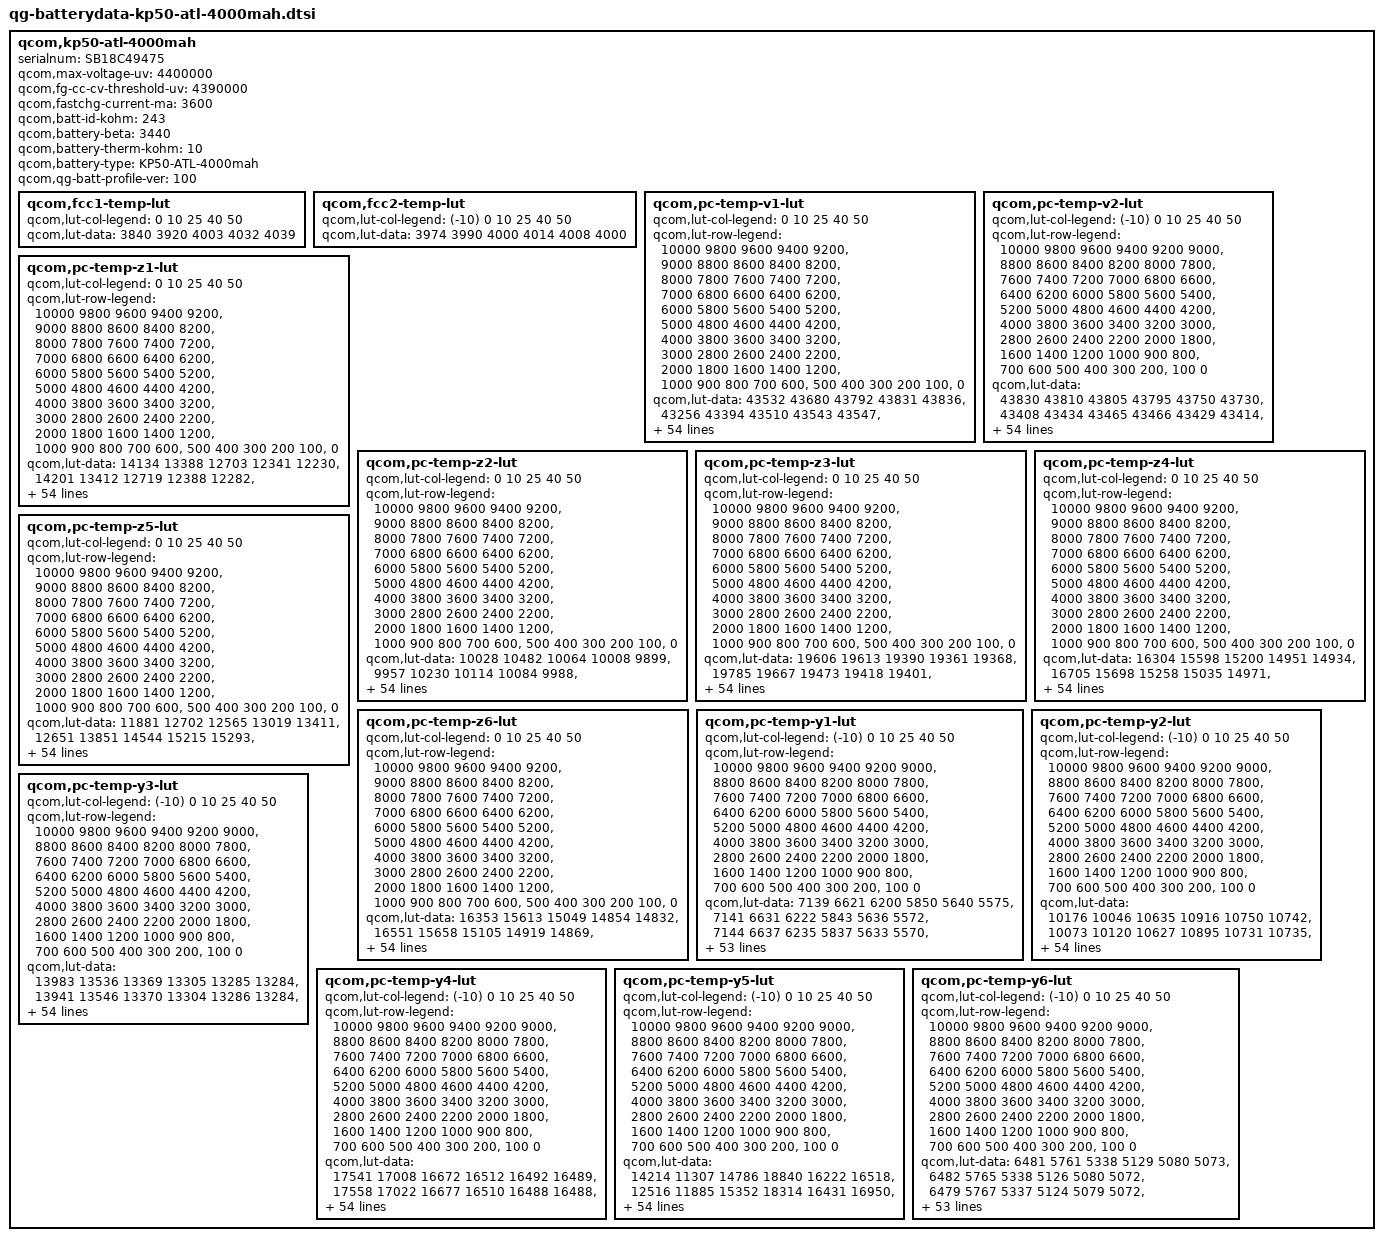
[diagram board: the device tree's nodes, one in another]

qcom,kp50-atl-4000mah {
    /* 3939372_Lenovo_KP50_ATL_4000mAh_PM6150_FG_averaged_MasterSlave_Mar25th2019 */
    serialnum = "SB18C49475";
    qcom,max-voltage-uv = <4400000>;
    qcom,fg-cc-cv-threshold-uv = <4390000>;
    qcom,fastchg-current-ma = <3600>;
    qcom,batt-id-kohm = <243>;
    qcom,battery-beta = <3440>;
    qcom,battery-therm-kohm = <10>;
    qcom,battery-type = "KP50-ATL-4000mah";
    qcom,qg-batt-profile-ver = <100>;

	qcom,fcc1-temp-lut {
		qcom,lut-col-legend = <0 10 25 40 50>;
		qcom,lut-data = <3840 3920 4003 4032 4039>;
	};

	qcom,fcc2-temp-lut {
		qcom,lut-col-legend = <(-10) 0 10 25 40 50>;
		qcom,lut-data = <3974 3990 4000 4014 4008 4000>;
	};

	qcom,pc-temp-v1-lut {
		qcom,lut-col-legend = <0 10 25 40 50>;
		qcom,lut-row-legend = <10000 9800 9600 9400 9200>,
			<9000 8800 8600 8400 8200>,
			<8000 7800 7600 7400 7200>,
			<7000 6800 6600 6400 6200>,
			<6000 5800 5600 5400 5200>,
			<5000 4800 4600 4400 4200>,
			<4000 3800 3600 3400 3200>,
			<3000 2800 2600 2400 2200>,
			<2000 1800 1600 1400 1200>,
			<1000 900 800 700 600>,
			<500 400 300 200 100>,
			<0>;
		qcom,lut-data = <43532 43680 43792 43831 43836>,
			<43256 43394 43510 43543 43547>,
			<43004 43131 43248 43283 43290>,
			<42765 42888 42996 43036 43046>,
			<42530 42654 42754 42796 42807>,
			<42302 42420 42519 42563 42575>,
			<42079 42190 42287 42331 42344>,
			<41863 41967 42060 42101 42114>,
			<41653 41747 41835 41874 41886>,
			<41452 41533 41611 41650 41662>,
			<41262 41330 41393 41429 41440>,
			<41068 41136 41188 41216 41224>,
			<40859 40937 40990 41009 41012>,
			<40641 40725 40786 40807 40807>,
			<40421 40511 40570 40600 40604>,
			<40193 40308 40364 40399 40409>,
			<39992 40113 40176 40214 40228>,
			<39840 39945 40003 40041 40058>,
			<39712 39807 39848 39877 39894>,
			<39588 39679 39717 39732 39743>,
			<39465 39541 39572 39581 39586>,
			<39345 39399 39379 39385 39389>,
			<39225 39238 39162 39154 39157>,
			<39106 39011 38967 38961 38964>,
			<38980 38775 38774 38803 38813>,
			<38831 38634 38627 38672 38687>,
			<38680 38542 38543 38574 38587>,
			<38564 38473 38480 38496 38505>,
			<38470 38420 38417 38420 38421>,
			<38396 38378 38353 38345 38329>,
			<38345 38337 38295 38275 38244>,
			<38307 38297 38241 38206 38177>,
			<38273 38259 38191 38141 38120>,
			<38243 38223 38142 38083 38062>,
			<38216 38189 38096 38035 38005>,
			<38187 38154 38051 37988 37949>,
			<38157 38121 38011 37941 37893>,
			<38121 38081 37972 37891 37836>,
			<38070 38021 37914 37825 37763>,
			<38002 37935 37828 37730 37663>,
			<37915 37836 37728 37624 37551>,
			<37790 37718 37620 37517 37442>,
			<37651 37583 37495 37397 37321>,
			<37496 37425 37336 37242 37159>,
			<37350 37277 37192 37105 37030>,
			<37248 37177 37092 37015 36954>,
			<37219 37150 37065 36983 36921>,
			<37191 37126 37044 36963 36900>,
			<37168 37103 37025 36941 36876>,
			<37130 37064 36978 36878 36802>,
			<36915 36840 36743 36610 36512>,
			<36475 36400 36312 36170 36068>,
			<35905 35827 35741 35595 35492>,
			<35126 35050 34963 34812 34707>,
			<33885 33812 33759 33588 33477>,
			<30000 30000 30000 30000 30000>;
	};

	qcom,pc-temp-v2-lut {
		qcom,lut-col-legend = <(-10) 0 10 25 40 50>;
		qcom,lut-row-legend = <10000 9800 9600 9400 9200 9000>,
			<8800 8600 8400 8200 8000 7800>,
			<7600 7400 7200 7000 6800 6600>,
			<6400 6200 6000 5800 5600 5400>,
			<5200 5000 4800 4600 4400 4200>,
			<4000 3800 3600 3400 3200 3000>,
			<2800 2600 2400 2200 2000 1800>,
			<1600 1400 1200 1000 900 800>,
			<700 600 500 400 300 200>,
			<100 0>;
		qcom,lut-data = <43830 43810 43805 43795 43750 43730>,
			<43408 43434 43465 43466 43429 43414>,
			<43034 43095 43154 43164 43133 43121>,
			<42720 42801 42877 42893 42865 42856>,
			<42454 42547 42630 42650 42623 42616>,
			<42211 42304 42393 42415 42389 42382>,
			<41984 42065 42153 42179 42155 42149>,
			<41770 41831 41919 41948 41923 41918>,
			<41551 41596 41692 41720 41696 41691>,
			<41320 41353 41471 41494 41472 41466>,
			<41118 41142 41259 41275 41252 41246>,
			<40983 40994 41062 41063 41037 41031>,
			<40863 40861 40870 40857 40827 40821>,
			<40632 40661 40660 40651 40624 40618>,
			<40134 40356 40428 40445 40425 40420>,
			<39693 40055 40205 40245 40234 40230>,
			<39496 39814 40009 40049 40051 40051>,
			<39356 39596 39823 39864 39876 39878>,
			<39210 39400 39629 39700 39712 39714>,
			<39064 39223 39429 39559 39563 39563>,
			<38910 39056 39233 39399 39398 39399>,
			<38717 38894 39039 39176 39185 39190>,
			<38512 38740 38855 38941 38960 38967>,
			<38376 38581 38699 38762 38779 38786>,
			<38290 38409 38562 38613 38625 38630>,
			<38219 38266 38440 38487 38494 38497>,
			<38153 38167 38334 38380 38385 38386>,
			<38094 38089 38237 38286 38289 38289>,
			<38038 38029 38145 38198 38202 38199>,
			<37987 37982 38053 38116 38124 38117>,
			<37938 37939 37977 38043 38054 38044>,
			<37890 37898 37917 37976 37990 37980>,
			<37841 37858 37867 37915 37931 37921>,
			<37791 37819 37825 37857 37868 37856>,
			<37740 37781 37792 37804 37803 37786>,
			<37687 37740 37758 37750 37730 37706>,
			<37631 37692 37720 37693 37640 37603>,
			<37573 37638 37679 37633 37545 37490>,
			<37507 37574 37624 37563 37463 37399>,
			<37428 37500 37553 37484 37390 37324>,
			<37343 37415 37469 37399 37311 37246>,
			<37258 37316 37363 37308 37220 37157>,
			<37172 37201 37240 37201 37115 37056>,
			<37095 37072 37102 37063 36983 36922>,
			<37019 36945 36969 36944 36877 36818>,
			<36936 36847 36876 36885 36828 36770>,
			<36884 36808 36846 36871 36816 36760>,
			<36826 36763 36804 36853 36802 36743>,
			<36754 36701 36758 36818 36766 36708>,
			<36623 36593 36664 36729 36658 36581>,
			<36359 36348 36397 36424 36321 36226>,
			<35915 35890 35905 35932 35815 35718>,
			<35270 35238 35255 35288 35156 35057>,
			<34349 34308 34341 34414 34261 34169>,
			<32925 32874 33061 33169 32975 32863>,
			<29479 28325 27871 28921 27928 27833>;
	};

	qcom,pc-temp-z1-lut {
		qcom,lut-col-legend = <0 10 25 40 50>;
		qcom,lut-row-legend = <10000 9800 9600 9400 9200>,
			<9000 8800 8600 8400 8200>,
			<8000 7800 7600 7400 7200>,
			<7000 6800 6600 6400 6200>,
			<6000 5800 5600 5400 5200>,
			<5000 4800 4600 4400 4200>,
			<4000 3800 3600 3400 3200>,
			<3000 2800 2600 2400 2200>,
			<2000 1800 1600 1400 1200>,
			<1000 900 800 700 600>,
			<500 400 300 200 100>,
			<0>;
		qcom,lut-data = <14134 13388 12703 12341 12230>,
			<14201 13412 12719 12388 12282>,
			<14175 13418 12725 12390 12288>,
			<14146 13411 12724 12390 12290>,
			<14120 13401 12712 12388 12289>,
			<14092 13388 12697 12383 12289>,
			<14082 13373 12686 12380 12289>,
			<14092 13362 12676 12377 12291>,
			<14102 13351 12668 12376 12293>,
			<14093 13340 12660 12378 12298>,
			<14052 13329 12655 12381 12303>,
			<14004 13315 12653 12382 12305>,
			<13956 13298 12653 12382 12306>,
			<13910 13265 12651 12382 12306>,
			<13884 13236 12647 12380 12305>,
			<13868 13230 12644 12378 12304>,
			<13858 13232 12643 12378 12305>,
			<13857 13238 12644 12380 12307>,
			<13859 13252 12646 12382 12309>,
			<13862 13266 12652 12385 12311>,
			<13868 13269 12657 12388 12313>,
			<13876 13271 12661 12389 12314>,
			<13889 13271 12665 12390 12315>,
			<13908 13275 12668 12391 12316>,
			<13921 13280 12673 12393 12318>,
			<13920 13284 12677 12396 12320>,
			<13915 13286 12680 12400 12323>,
			<13913 13286 12684 12403 12327>,
			<13901 13286 12689 12407 12331>,
			<13890 13287 12695 12413 12334>,
			<13891 13293 12702 12418 12338>,
			<13898 13304 12708 12423 12343>,
			<13905 13317 12714 12428 12348>,
			<13915 13335 12722 12434 12353>,
			<13929 13355 12730 12441 12359>,
			<13951 13360 12740 12448 12365>,
			<13989 13358 12749 12453 12370>,
			<14016 13355 12757 12459 12375>,
			<14028 13358 12766 12465 12379>,
			<14041 13370 12775 12471 12383>,
			<14056 13382 12784 12478 12387>,
			<14091 13396 12795 12485 12392>,
			<14121 13414 12805 12492 12398>,
			<14143 13447 12809 12497 12402>,
			<14158 13435 12826 12505 12407>,
			<14120 13475 12837 12508 12408>,
			<14130 13443 12827 12508 12408>,
			<14122 13440 12834 12509 12410>,
			<14089 13423 12833 12515 12415>,
			<14129 13444 12839 12520 12420>,
			<14177 13442 12853 12527 12427>,
			<14147 13459 12870 12538 12435>,
			<14269 13501 12882 12548 12447>,
			<14263 13534 12909 12567 12463>,
			<14263 13534 12909 12567 12463>,
			<14263 13534 12909 12567 12463>;
	};

	qcom,pc-temp-z2-lut {
		qcom,lut-col-legend = <0 10 25 40 50>;
		qcom,lut-row-legend = <10000 9800 9600 9400 9200>,
			<9000 8800 8600 8400 8200>,
			<8000 7800 7600 7400 7200>,
			<7000 6800 6600 6400 6200>,
			<6000 5800 5600 5400 5200>,
			<5000 4800 4600 4400 4200>,
			<4000 3800 3600 3400 3200>,
			<3000 2800 2600 2400 2200>,
			<2000 1800 1600 1400 1200>,
			<1000 900 800 700 600>,
			<500 400 300 200 100>,
			<0>;
		qcom,lut-data = <10028 10482 10064 10008 9899>,
			<9957 10230 10114 10084 9988>,
			<10007 10128 10203 10180 10110>,
			<10061 10116 10227 10219 10177>,
			<10084 10106 10210 10205 10176>,
			<10102 10089 10188 10178 10172>,
			<10110 10069 10164 10154 10164>,
			<10114 10053 10138 10125 10144>,
			<10117 10040 10117 10106 10134>,
			<10115 10032 10098 10094 10127>,
			<10101 10028 10089 10087 10114>,
			<10082 10025 10178 10089 10109>,
			<10052 10025 10392 10092 10102>,
			<10017 10033 10454 10093 10096>,
			<9996 10048 10301 10100 10100>,
			<9982 10091 10152 10110 10106>,
			<9974 10217 10133 10078 10079>,
			<9978 10297 10123 9982 9993>,
			<9990 10247 10123 9942 9952>,
			<10002 10164 10139 9955 9966>,
			<10013 10158 10166 9982 9996>,
			<10025 10184 10246 10093 10114>,
			<10036 10208 10350 10322 10388>,
			<10049 10225 10360 10395 10493>,
			<10064 10238 10293 10215 10289>,
			<10084 10248 10235 10037 10071>,
			<10104 10256 10212 10037 10060>,
			<10118 10259 10196 10061 10079>,
			<10130 10258 10201 10072 10122>,
			<10138 10256 10240 10074 10340>,
			<10139 10254 10272 10076 10538>,
			<10139 10251 10282 10137 10476>,
			<10140 10249 10289 10264 10277>,
			<10145 10251 10294 10293 10129>,
			<10152 10258 10299 10199 10016>,
			<10158 10264 10302 10112 9952>,
			<10166 10269 10302 10099 9968>,
			<10175 10275 10302 10101 10015>,
			<10185 10285 10311 10125 10056>,
			<10196 10299 10348 10225 10098>,
			<10208 10309 10373 10298 10122>,
			<10219 10316 10366 10283 10121>,
			<10235 10323 10358 10256 10118>,
			<10262 10329 10368 10248 10222>,
			<10497 10450 10399 10218 10216>,
			<10535 10508 10409 10183 10113>,
			<10546 10506 10386 10170 10086>,
			<10556 10505 10353 10181 10096>,
			<10542 10513 10360 10196 10125>,
			<10489 10603 10399 10276 10196>,
			<10630 10588 10408 10201 10093>,
			<10589 10533 10337 10041 9935>,
			<10332 10464 10261 9987 9880>,
			<10066 10330 10188 9964 9846>,
			<10066 10330 10188 9964 9846>,
			<10066 10330 10188 9964 9846>;
	};

	qcom,pc-temp-z3-lut {
		qcom,lut-col-legend = <0 10 25 40 50>;
		qcom,lut-row-legend = <10000 9800 9600 9400 9200>,
			<9000 8800 8600 8400 8200>,
			<8000 7800 7600 7400 7200>,
			<7000 6800 6600 6400 6200>,
			<6000 5800 5600 5400 5200>,
			<5000 4800 4600 4400 4200>,
			<4000 3800 3600 3400 3200>,
			<3000 2800 2600 2400 2200>,
			<2000 1800 1600 1400 1200>,
			<1000 900 800 700 600>,
			<500 400 300 200 100>,
			<0>;
		qcom,lut-data = <19606 19613 19390 19361 19368>,
			<19785 19667 19473 19418 19401>,
			<19851 19680 19509 19440 19419>,
			<19877 19692 19520 19451 19430>,
			<19874 19700 19525 19457 19438>,
			<19859 19698 19527 19460 19444>,
			<19841 19691 19523 19460 19446>,
			<19813 19683 19514 19460 19448>,
			<19786 19672 19508 19459 19449>,
			<19775 19660 19504 19457 19448>,
			<19771 19652 19501 19453 19444>,
			<19772 19644 19501 19448 19439>,
			<19782 19636 19506 19440 19433>,
			<19796 19624 19507 19434 19427>,
			<19801 19614 19497 19432 19423>,
			<19801 19611 19486 19430 19419>,
			<19798 19612 19477 19426 19412>,
			<19778 19610 19467 19418 19403>,
			<19739 19581 19457 19409 19395>,
			<19715 19544 19444 19398 19386>,
			<19702 19539 19437 19391 19380>,
			<19695 19549 19446 19395 19383>,
			<19695 19561 19463 19408 19393>,
			<19698 19574 19465 19412 19396>,
			<19704 19587 19458 19396 19378>,
			<19720 19589 19449 19378 19358>,
			<19740 19587 19441 19370 19353>,
			<19744 19583 19435 19365 19351>,
			<19741 19579 19434 19364 19354>,
			<19735 19574 19435 19371 19398>,
			<19728 19569 19438 19383 19442>,
			<19717 19565 19444 19401 19440>,
			<19707 19562 19451 19425 19427>,
			<19695 19560 19456 19431 19416>,
			<19684 19559 19461 19423 19405>,
			<19676 19557 19464 19413 19396>,
			<19669 19553 19457 19402 19386>,
			<19662 19549 19446 19393 19377>,
			<19655 19546 19443 19390 19374>,
			<19649 19544 19442 19392 19373>,
			<19647 19542 19441 19393 19373>,
			<19646 19537 19433 19391 19376>,
			<19644 19531 19426 19389 19381>,
			<19625 19521 19424 19390 19391>,
			<19548 19488 19414 19387 19390>,
			<19525 19468 19403 19369 19367>,
			<19502 19456 19396 19365 19362>,
			<19496 19451 19390 19356 19347>,
			<19465 19448 19378 19350 19342>,
			<19366 19418 19366 19341 19340>,
			<19483 19441 19377 19369 19369>,
			<19478 19440 19379 19391 19389>,
			<19419 19437 19384 19395 19388>,
			<19380 19367 19387 19382 19384>,
			<19380 19367 19387 19382 19384>,
			<19380 19367 19387 19382 19384>;
	};

	qcom,pc-temp-z4-lut {
		qcom,lut-col-legend = <0 10 25 40 50>;
		qcom,lut-row-legend = <10000 9800 9600 9400 9200>,
			<9000 8800 8600 8400 8200>,
			<8000 7800 7600 7400 7200>,
			<7000 6800 6600 6400 6200>,
			<6000 5800 5600 5400 5200>,
			<5000 4800 4600 4400 4200>,
			<4000 3800 3600 3400 3200>,
			<3000 2800 2600 2400 2200>,
			<2000 1800 1600 1400 1200>,
			<1000 900 800 700 600>,
			<500 400 300 200 100>,
			<0>;
		qcom,lut-data = <16304 15598 15200 14951 14934>,
			<16705 15698 15258 15035 14971>,
			<16416 15683 15176 14998 14950>,
			<16077 15492 15096 14957 14923>,
			<15862 15285 15020 14920 14895>,
			<15685 15169 14958 14885 14865>,
			<15549 15081 14914 14855 14840>,
			<15446 15016 14879 14830 14817>,
			<15361 14965 14849 14808 14797>,
			<15281 14924 14825 14786 14777>,
			<15205 14887 14801 14768 14760>,
			<15133 14855 14768 14756 14751>,
			<15060 14831 14730 14747 14745>,
			<14993 14813 14717 14740 14740>,
			<14949 14799 14728 14733 14736>,
			<14917 14781 14737 14728 14731>,
			<14893 14754 14733 14722 14726>,
			<14874 14736 14726 14716 14721>,
			<14858 14743 14717 14711 14715>,
			<14843 14754 14705 14704 14707>,
			<14828 14752 14699 14699 14702>,
			<14814 14739 14717 14715 14717>,
			<14801 14732 14757 14766 14770>,
			<14789 14787 14799 14813 14818>,
			<14783 14871 14862 14859 14859>,
			<14793 14888 14900 14890 14886>,
			<14809 14885 14893 14888 14884>,
			<14819 14881 14876 14875 14868>,
			<14829 14870 14859 14859 14844>,
			<14835 14849 14840 14835 14782>,
			<14832 14831 14819 14807 14726>,
			<14823 14816 14797 14772 14715>,
			<14813 14801 14774 14735 14709>,
			<14805 14785 14755 14719 14705>,
			<14796 14771 14738 14713 14703>,
			<14787 14759 14727 14709 14701>,
			<14779 14749 14722 14708 14700>,
			<14773 14742 14719 14707 14700>,
			<14768 14743 14720 14708 14702>,
			<14764 14746 14727 14720 14720>,
			<14764 14747 14732 14729 14735>,
			<14764 14747 14732 14726 14727>,
			<14764 14746 14732 14722 14715>,
			<14761 14744 14729 14721 14714>,
			<14741 14721 14711 14709 14702>,
			<14743 14712 14696 14698 14689>,
			<14757 14713 14693 14693 14686>,
			<14757 14707 14684 14683 14680>,
			<14783 14701 14679 14662 14655>,
			<14886 14722 14682 14661 14645>,
			<14754 14710 14699 14680 14676>,
			<14790 14729 14717 14679 14680>,
			<14874 14742 14717 14683 14688>,
			<14937 14827 14720 14701 14698>,
			<14937 14827 14720 14701 14698>,
			<14937 14827 14720 14701 14698>;
	};

	qcom,pc-temp-z5-lut {
		qcom,lut-col-legend = <0 10 25 40 50>;
		qcom,lut-row-legend = <10000 9800 9600 9400 9200>,
			<9000 8800 8600 8400 8200>,
			<8000 7800 7600 7400 7200>,
			<7000 6800 6600 6400 6200>,
			<6000 5800 5600 5400 5200>,
			<5000 4800 4600 4400 4200>,
			<4000 3800 3600 3400 3200>,
			<3000 2800 2600 2400 2200>,
			<2000 1800 1600 1400 1200>,
			<1000 900 800 700 600>,
			<500 400 300 200 100>,
			<0>;
		qcom,lut-data = <11881 12702 12565 13019 13411>,
			<12651 13851 14544 15215 15293>,
			<13143 14559 15673 16498 16666>,
			<13495 15079 16458 17366 17757>,
			<13739 15568 17097 17940 18640>,
			<13930 16074 17503 18390 19381>,
			<14071 16542 17679 18854 20170>,
			<14140 16927 17801 19308 21130>,
			<14185 17235 18050 19830 21928>,
			<14281 17587 18546 20567 22925>,
			<14506 18139 19241 21320 23873>,
			<14863 18882 21025 21823 24129>,
			<15615 19690 24081 22228 24442>,
			<16733 20628 25371 22378 24851>,
			<17804 21716 24763 23383 25806>,
			<19068 23107 23881 24691 26746>,
			<19821 24956 23741 24787 26606>,
			<19425 25824 23636 24359 25720>,
			<18549 23703 23666 24322 25304>,
			<18250 20639 24067 24801 25751>,
			<18740 21125 24867 25571 26652>,
			<19671 26302 32201 28434 28657>,
			<20920 32451 43347 34644 32612>,
			<22986 39729 44392 36582 33964>,
			<26031 46485 36612 29060 27015>,
			<34229 46967 29222 20651 18871>,
			<44091 42106 25167 18014 16611>,
			<46177 36989 22169 16458 15408>,
			<44892 33756 21238 16100 15546>,
			<43208 31116 20899 16367 22155>,
			<40908 29643 20771 16913 28530>,
			<37139 28663 21421 19908 28460>,
			<33907 28173 23024 25590 27528>,
			<31212 28491 25439 27615 27169>,
			<29067 29299 30021 27935 27173>,
			<27963 29856 32752 28041 27174>,
			<27189 30186 32257 27732 27046>,
			<26786 30464 31340 27184 26784>,
			<26634 30761 30885 27137 26484>,
			<26515 31066 30704 27947 26121>,
			<26654 31097 30392 28584 25647>,
			<27752 29581 26843 26017 24677>,
			<28055 27742 23327 22707 23798>,
			<26784 25949 23673 23247 27550>,
			<25651 26526 23896 23302 28188>,
			<23470 24885 23224 19731 20584>,
			<19624 22076 21184 18928 19054>,
			<18982 21483 20555 17883 17071>,
			<17315 21463 19256 19079 19095>,
			<13369 17457 17789 18022 20124>,
			<18856 20521 18081 20163 22086>,
			<16992 18346 16104 20508 21134>,
			<13930 17058 16000 19442 18681>,
			<12412 12961 15678 15834 15880>,
			<12412 12961 15678 15834 15880>,
			<12412 12961 15678 15834 15880>;
	};

	qcom,pc-temp-z6-lut {
		qcom,lut-col-legend = <0 10 25 40 50>;
		qcom,lut-row-legend = <10000 9800 9600 9400 9200>,
			<9000 8800 8600 8400 8200>,
			<8000 7800 7600 7400 7200>,
			<7000 6800 6600 6400 6200>,
			<6000 5800 5600 5400 5200>,
			<5000 4800 4600 4400 4200>,
			<4000 3800 3600 3400 3200>,
			<3000 2800 2600 2400 2200>,
			<2000 1800 1600 1400 1200>,
			<1000 900 800 700 600>,
			<500 400 300 200 100>,
			<0>;
		qcom,lut-data = <16353 15613 15049 14854 14832>,
			<16551 15658 15105 14919 14869>,
			<16415 15648 15092 14917 14870>,
			<16245 15555 15073 14912 14871>,
			<16118 15450 15040 14901 14865>,
			<16001 15384 15007 14885 14855>,
			<15905 15330 14983 14873 14846>,
			<15825 15286 14961 14862 14838>,
			<15757 15249 14944 14852 14830>,
			<15701 15219 14930 14842 14822>,
			<15653 15193 14917 14832 14814>,
			<15608 15171 14904 14824 14807>,
			<15560 15149 14890 14816 14801>,
			<15516 15126 14884 14809 14795>,
			<15484 15107 14881 14804 14790>,
			<15462 15095 14877 14800 14785>,
			<15440 15086 14871 14795 14779>,
			<15413 15077 14862 14788 14772>,
			<15385 15063 14853 14781 14765>,
			<15368 15051 14842 14772 14756>,
			<15357 15050 14836 14766 14750>,
			<15350 15052 14849 14776 14759>,
			<15350 15056 14875 14806 14790>,
			<15351 15087 14896 14825 14808>,
			<15353 15131 14919 14835 14814>,
			<15366 15140 14932 14841 14818>,
			<15387 15139 14927 14839 14815>,
			<15395 15138 14916 14830 14807>,
			<15400 15133 14909 14823 14801>,
			<15402 15123 14903 14818 14800>,
			<15400 15115 14897 14813 14798>,
			<15392 15108 14892 14809 14793>,
			<15385 15102 14887 14807 14785>,
			<15378 15097 14883 14803 14778>,
			<15372 15092 14880 14797 14772>,
			<15369 15089 14878 14792 14767>,
			<15366 15086 14873 14786 14762>,
			<15365 15084 14868 14781 14757>,
			<15367 15086 14868 14781 14757>,
			<15373 15091 14872 14787 14764>,
			<15380 15096 14875 14791 14769>,
			<15391 15099 14874 14790 14768>,
			<15399 15100 14872 14788 14767>,
			<15404 15101 14872 14789 14772>,
			<15382 15087 14863 14784 14767>,
			<15374 15076 14853 14770 14750>,
			<15369 15071 14847 14766 14746>,
			<15367 15067 14841 14757 14736>,
			<15365 15063 14833 14746 14723>,
			<15364 15061 14830 14741 14717>,
			<15380 15074 14846 14765 14747>,
			<15402 15089 14858 14780 14763>,
			<15423 15103 14866 14787 14770>,
			<15453 15119 14876 14793 14777>,
			<15453 15119 14876 14793 14777>,
			<15453 15119 14876 14793 14777>;
	};

	qcom,pc-temp-y1-lut {
		qcom,lut-col-legend = <(-10) 0 10 25 40 50>;
		qcom,lut-row-legend = <10000 9800 9600 9400 9200 9000>,
			<8800 8600 8400 8200 8000 7800>,
			<7600 7400 7200 7000 6800 6600>,
			<6400 6200 6000 5800 5600 5400>,
			<5200 5000 4800 4600 4400 4200>,
			<4000 3800 3600 3400 3200 3000>,
			<2800 2600 2400 2200 2000 1800>,
			<1600 1400 1200 1000 900 800>,
			<700 600 500 400 300 200>,
			<100 0>;
		qcom,lut-data = <7139 6621 6200 5850 5640 5575>,
			<7141 6631 6222 5843 5636 5572>,
			<7144 6637 6235 5837 5633 5570>,
			<7148 6640 6242 5831 5630 5568>,
			<7150 6640 6244 5826 5626 5567>,
			<7152 6640 6244 5821 5624 5565>,
			<7153 6634 6237 5817 5621 5564>,
			<7154 6624 6227 5813 5619 5563>,
			<7154 6622 6221 5810 5618 5562>,
			<7152 6622 6217 5807 5617 5561>,
			<7150 6622 6214 5804 5616 5561>,
			<7148 6622 6213 5801 5615 5560>,
			<7145 6622 6215 5798 5614 5561>,
			<7148 6623 6214 5796 5613 5560>,
			<7172 6625 6212 5794 5612 5560>,
			<7192 6628 6210 5793 5611 5560>,
			<7186 6633 6214 5795 5613 5561>,
			<7171 6640 6220 5799 5615 5562>,
			<7161 6643 6223 5801 5615 5563>,
			<7154 6640 6224 5802 5615 5563>,
			<7150 6637 6225 5803 5616 5564>,
			<7154 6634 6225 5806 5616 5565>,
			<7164 6631 6226 5809 5618 5565>,
			<7166 6634 6228 5813 5620 5567>,
			<7160 6642 6232 5818 5623 5569>,
			<7150 6648 6234 5823 5627 5572>,
			<7140 6651 6234 5828 5630 5574>,
			<7127 6654 6232 5833 5633 5576>,
			<7122 6653 6235 5838 5636 5579>,
			<7127 6639 6246 5844 5641 5583>,
			<7132 6626 6256 5850 5645 5586>,
			<7132 6624 6262 5856 5650 5590>,
			<7130 6623 6266 5863 5656 5593>,
			<7127 6624 6267 5870 5660 5596>,
			<7125 6632 6262 5876 5664 5600>,
			<7123 6639 6259 5881 5667 5602>,
			<7121 6632 6261 5885 5670 5604>,
			<7120 6619 6264 5888 5672 5606>,
			<7119 6616 6267 5892 5674 5608>,
			<7121 6627 6269 5896 5676 5611>,
			<7121 6636 6272 5901 5677 5612>,
			<7112 6631 6276 5907 5679 5613>,
			<7102 6624 6279 5915 5682 5614>,
			<7107 6632 6281 5923 5688 5619>,
			<7120 6641 6296 5938 5695 5624>,
			<7136 6659 6297 5941 5701 5627>,
			<7204 6653 6315 5947 5700 5627>,
			<7205 6652 6303 5944 5699 5626>,
			<7217 6672 6315 5943 5699 5627>,
			<7191 6669 6306 5948 5699 5628>,
			<7177 6652 6309 5951 5703 5633>,
			<7211 6684 6325 5969 5713 5640>,
			<7207 6705 6339 6000 5724 5648>,
			<7281 6723 6362 6031 5742 5660>,
			<7281 6723 6362 6031 5742 5660>,
			<7281 6723 6362 6031 5742 5660>;
	};

	qcom,pc-temp-y2-lut {
		qcom,lut-col-legend = <(-10) 0 10 25 40 50>;
		qcom,lut-row-legend = <10000 9800 9600 9400 9200 9000>,
			<8800 8600 8400 8200 8000 7800>,
			<7600 7400 7200 7000 6800 6600>,
			<6400 6200 6000 5800 5600 5400>,
			<5200 5000 4800 4600 4400 4200>,
			<4000 3800 3600 3400 3200 3000>,
			<2800 2600 2400 2200 2000 1800>,
			<1600 1400 1200 1000 900 800>,
			<700 600 500 400 300 200>,
			<100 0>;
		qcom,lut-data = <10176 10046 10635 10916 10750 10742>,
			<10073 10120 10627 10895 10731 10735>,
			<10029 10181 10619 10873 10706 10716>,
			<10030 10228 10612 10850 10679 10691>,
			<10062 10258 10605 10826 10656 10666>,
			<10110 10269 10598 10802 10643 10647>,
			<10212 10252 10591 10773 10637 10625>,
			<10333 10225 10584 10746 10633 10599>,
			<10351 10244 10584 10736 10628 10586>,
			<10308 10381 10591 10732 10620 10577>,
			<10277 10480 10600 10731 10612 10573>,
			<10349 10483 10611 10735 10602 10581>,
			<10475 10479 10630 10740 10593 10592>,
			<10446 10490 10669 10750 10601 10590>,
			<10022 10536 10763 10774 10649 10562>,
			<9693 10592 10825 10804 10696 10544>,
			<9678 10642 10831 10846 10721 10555>,
			<9673 10699 10835 10902 10747 10584>,
			<9671 10777 10846 10965 10800 10638>,
			<9670 10901 10872 11043 10904 10761>,
			<9669 10973 10900 11077 10966 10836>,
			<9667 10948 10923 11049 10939 10818>,
			<9665 10896 10947 11009 10888 10786>,
			<9664 10870 10974 11002 10867 10779>,
			<9663 10854 11004 11003 10834 10781>,
			<9662 10836 11038 11006 10823 10784>,
			<9662 10688 11090 11031 10850 10790>,
			<9661 10395 11138 11075 10888 10803>,
			<9660 10212 11144 11122 10914 10823>,
			<9660 9899 11134 11182 10935 10862>,
			<9659 9707 11124 11224 10960 10897>,
			<9659 9693 11120 11247 11019 10922>,
			<9659 9685 11115 11262 11084 10946>,
			<9658 9680 11106 11260 11112 10991>,
			<9658 9676 11084 11249 11131 11071>,
			<9658 9673 11058 11238 11136 11113>,
			<9657 9670 11036 11223 11063 11044>,
			<9657 9667 11011 11199 10967 10929>,
			<9657 9665 10978 11171 10965 10890>,
			<9657 9663 10933 11138 11009 10882>,
			<9657 9661 10880 11117 11030 10883>,
			<9656 9659 10815 11105 10988 10902>,
			<9656 9658 10741 11090 10928 10913>,
			<9656 9657 10665 11038 10879 10802>,
			<9656 9656 10483 10973 10785 10663>,
			<9655 9655 10175 10954 10754 10606>,
			<9655 9655 10101 10945 10790 10646>,
			<9655 9655 9820 10927 10819 10682>,
			<9655 9654 9748 10946 10812 10702>,
			<9654 9654 9723 10934 10819 10662>,
			<9654 9654 9694 10889 10759 10578>,
			<9653 9653 9675 10801 10697 10518>,
			<9652 9653 9665 10724 10607 10447>,
			<9650 9652 9659 10661 10516 10361>,
			<9650 9652 9659 10661 10516 10361>,
			<9650 9652 9659 10661 10516 10361>;
	};

	qcom,pc-temp-y3-lut {
		qcom,lut-col-legend = <(-10) 0 10 25 40 50>;
		qcom,lut-row-legend = <10000 9800 9600 9400 9200 9000>,
			<8800 8600 8400 8200 8000 7800>,
			<7600 7400 7200 7000 6800 6600>,
			<6400 6200 6000 5800 5600 5400>,
			<5200 5000 4800 4600 4400 4200>,
			<4000 3800 3600 3400 3200 3000>,
			<2800 2600 2400 2200 2000 1800>,
			<1600 1400 1200 1000 900 800>,
			<700 600 500 400 300 200>,
			<100 0>;
		qcom,lut-data = <13983 13536 13369 13305 13285 13284>,
			<13941 13546 13370 13304 13286 13284>,
			<13915 13554 13372 13304 13286 13285>,
			<13902 13561 13374 13304 13287 13285>,
			<13898 13566 13376 13305 13288 13286>,
			<13897 13567 13377 13305 13289 13287>,
			<13917 13566 13378 13306 13289 13288>,
			<13949 13562 13378 13306 13290 13289>,
			<13922 13561 13379 13307 13290 13289>,
			<13707 13559 13381 13307 13291 13289>,
			<13552 13555 13382 13307 13292 13290>,
			<13572 13520 13383 13308 13293 13290>,
			<13610 13467 13384 13310 13293 13291>,
			<13611 13459 13383 13312 13294 13292>,
			<13558 13479 13374 13314 13299 13293>,
			<13513 13492 13368 13314 13301 13294>,
			<13507 13479 13368 13313 13302 13295>,
			<13507 13453 13369 13311 13302 13296>,
			<13514 13433 13368 13312 13302 13297>,
			<13538 13418 13361 13314 13302 13299>,
			<13555 13404 13353 13315 13302 13300>,
			<13539 13384 13347 13312 13298 13296>,
			<13506 13366 13341 13306 13292 13289>,
			<13497 13361 13336 13302 13289 13286>,
			<13512 13360 13332 13298 13288 13284>,
			<13534 13359 13328 13297 13287 13283>,
			<13555 13353 13326 13297 13286 13284>,
			<13580 13345 13324 13298 13285 13284>,
			<13607 13344 13322 13297 13285 13284>,
			<13638 13348 13320 13297 13285 13282>,
			<13671 13350 13318 13296 13285 13281>,
			<13704 13350 13318 13296 13286 13281>,
			<13738 13353 13317 13297 13287 13283>,
			<13774 13361 13318 13297 13287 13284>,
			<13812 13380 13320 13297 13288 13286>,
			<13851 13403 13323 13297 13288 13286>,
			<13893 13427 13326 13298 13286 13285>,
			<13938 13456 13329 13299 13285 13283>,
			<13983 13490 13331 13299 13285 13283>,
			<14026 13535 13332 13298 13288 13286>,
			<14070 13589 13333 13297 13290 13289>,
			<14115 13655 13334 13300 13290 13290>,
			<14162 13737 13336 13302 13290 13290>,
			<14222 13836 13340 13299 13288 13287>,
			<14298 13953 13345 13301 13288 13288>,
			<14339 14009 13348 13303 13294 13293>,
			<14350 14066 13354 13309 13300 13298>,
			<14432 14150 13363 13315 13305 13301>,
			<14528 14231 13393 13320 13306 13302>,
			<14638 14320 13424 13324 13304 13299>,
			<14773 14399 13441 13318 13300 13295>,
			<14973 14504 13469 13321 13302 13297>,
			<15290 14692 13565 13330 13308 13305>,
			<16338 14961 13749 13348 13319 13316>,
			<16338 14961 13749 13348 13319 13316>,
			<16338 14961 13749 13348 13319 13316>;
	};

	qcom,pc-temp-y4-lut {
		qcom,lut-col-legend = <(-10) 0 10 25 40 50>;
		qcom,lut-row-legend = <10000 9800 9600 9400 9200 9000>,
			<8800 8600 8400 8200 8000 7800>,
			<7600 7400 7200 7000 6800 6600>,
			<6400 6200 6000 5800 5600 5400>,
			<5200 5000 4800 4600 4400 4200>,
			<4000 3800 3600 3400 3200 3000>,
			<2800 2600 2400 2200 2000 1800>,
			<1600 1400 1200 1000 900 800>,
			<700 600 500 400 300 200>,
			<100 0>;
		qcom,lut-data = <17541 17008 16672 16512 16492 16489>,
			<17558 17022 16677 16510 16488 16488>,
			<17567 17041 16682 16509 16486 16487>,
			<17567 17061 16687 16508 16484 16485>,
			<17560 17077 16691 16508 16484 16484>,
			<17547 17086 16693 16508 16484 16483>,
			<17437 17090 16693 16510 16485 16483>,
			<17269 17092 16692 16514 16487 16483>,
			<17300 17091 16693 16519 16490 16484>,
			<17716 17084 16699 16527 16493 16486>,
			<18017 17079 16708 16535 16497 16489>,
			<17980 17230 16727 16542 16503 16492>,
			<17881 17474 16757 16549 16509 16496>,
			<17743 17489 16792 16561 16514 16500>,
			<17494 17268 16838 16579 16519 16506>,
			<17302 17078 16862 16599 16525 16512>,
			<17251 17020 16850 16618 16535 16519>,
			<17221 16982 16823 16637 16549 16528>,
			<17171 16952 16791 16660 16570 16543>,
			<17086 16928 16743 16688 16606 16569>,
			<16998 16904 16697 16700 16624 16583>,
			<16913 16878 16653 16643 16595 16567>,
			<16836 16848 16616 16558 16546 16536>,
			<16812 16793 16599 16523 16515 16513>,
			<16807 16681 16590 16503 16490 16491>,
			<16805 16608 16585 16496 16480 16482>,
			<16806 16612 16584 16498 16482 16482>,
			<16810 16627 16583 16501 16486 16483>,
			<16813 16642 16578 16506 16491 16486>,
			<16814 16666 16560 16513 16502 16496>,
			<16815 16688 16549 16520 16513 16508>,
			<16819 16703 16551 16528 16527 16521>,
			<16825 16716 16555 16535 16538 16533>,
			<16831 16728 16562 16537 16540 16537>,
			<16838 16739 16577 16539 16539 16539>,
			<16844 16749 16593 16539 16536 16539>,
			<16845 16761 16609 16534 16518 16521>,
			<16846 16771 16624 16527 16495 16493>,
			<16846 16776 16635 16524 16493 16489>,
			<16839 16778 16643 16522 16496 16495>,
			<16832 16779 16647 16522 16501 16503>,
			<16834 16779 16648 16531 16509 16513>,
			<16843 16776 16648 16536 16513 16519>,
			<16859 16760 16644 16529 16490 16487>,
			<16887 16758 16644 16523 16481 16472>,
			<16897 16759 16648 16524 16494 16501>,
			<16893 16773 16670 16541 16526 16541>,
			<16921 16813 16717 16571 16568 16586>,
			<16952 16869 16768 16618 16611 16627>,
			<16970 16922 16824 16651 16609 16604>,
			<16950 16933 16829 16588 16523 16516>,
			<16916 16908 16822 16581 16510 16508>,
			<16925 16896 16857 16611 16520 16511>,
			<17215 16943 16931 16683 16575 16556>,
			<17215 16943 16931 16683 16575 16556>,
			<17215 16943 16931 16683 16575 16556>;
	};

	qcom,pc-temp-y5-lut {
		qcom,lut-col-legend = <(-10) 0 10 25 40 50>;
		qcom,lut-row-legend = <10000 9800 9600 9400 9200 9000>,
			<8800 8600 8400 8200 8000 7800>,
			<7600 7400 7200 7000 6800 6600>,
			<6400 6200 6000 5800 5600 5400>,
			<5200 5000 4800 4600 4400 4200>,
			<4000 3800 3600 3400 3200 3000>,
			<2800 2600 2400 2200 2000 1800>,
			<1600 1400 1200 1000 900 800>,
			<700 600 500 400 300 200>,
			<100 0>;
		qcom,lut-data = <14214 11307 14786 18840 16222 16518>,
			<12516 11885 15352 18314 16431 16950>,
			<11764 12496 15770 17806 16506 17196>,
			<11743 13079 16055 17317 16476 17307>,
			<12239 13571 16217 16849 16373 17337>,
			<13041 13910 16269 16405 16226 17335>,
			<15221 14141 16075 15997 15870 17231>,
			<18000 14300 15751 15599 15392 16998>,
			<18011 14220 15640 15132 15102 16662>,
			<14479 13628 15631 14538 14803 15929>,
			<11939 13226 15584 14092 14534 15318>,
			<14189 13372 14913 13859 14159 15005>,
			<18196 13775 13949 13679 13781 14768>,
			<18653 14735 13846 13513 13797 14594>,
			<15007 17523 14401 13337 14140 14438>,
			<12218 19306 15238 13258 14344 14390>,
			<12458 18221 17019 13356 14187 14275>,
			<13245 16426 19108 13608 13974 14066>,
			<14309 16116 19655 14314 13992 14056>,
			<16242 16595 19747 16306 14299 14292>,
			<17550 17103 19715 18116 14769 14621>,
			<16208 17518 19412 19447 16245 15699>,
			<13328 17948 18903 20384 17934 17045>,
			<12219 18284 18379 20101 18173 17373>,
			<12003 18955 17731 18681 18059 17444>,
			<11901 19180 17400 17837 17880 17431>,
			<11867 17320 17661 17888 17121 17094>,
			<11845 14314 18106 18004 16111 16435>,
			<11852 13208 18333 17830 15769 15680>,
			<11976 12824 18478 17603 15612 14658>,
			<12132 12660 18531 17504 15555 14123>,
			<12234 12643 18013 17880 15825 14393>,
			<12323 12661 17252 18529 16387 15033>,
			<12406 12737 17148 19003 17135 15953>,
			<12477 12987 17375 19432 18263 17531>,
			<12554 13187 17586 19706 18783 18373>,
			<12709 13237 17763 19898 18112 18023>,
			<12946 13269 17936 20022 17230 17449>,
			<13033 13311 17903 19554 17340 17553>,
			<12931 13381 17615 17949 18270 18710>,
			<12749 13414 17264 17155 18768 19628>,
			<12458 13333 16843 17364 18331 19745>,
			<12123 13277 16582 17470 17700 19622>,
			<12109 13224 16608 16360 17162 18786>,
			<12156 12970 16241 16106 16046 17249>,
			<12316 12893 14712 15852 15748 15470>,
			<12332 13003 14368 16159 15950 15157>,
			<12403 12960 13186 16340 15840 14632>,
			<12696 12848 13414 16131 15254 14366>,
			<12845 13074 14069 16272 15011 14137>,
			<12771 13206 13654 16668 16001 14710>,
			<12641 13001 12986 17076 16757 15057>,
			<12436 12883 12906 17307 17283 16584>,
			<11712 12784 12839 18858 20685 21116>,
			<11712 12784 12839 18858 20685 21116>,
			<11712 12784 12839 18858 20685 21116>;
	};

	qcom,pc-temp-y6-lut {
		qcom,lut-col-legend = <(-10) 0 10 25 40 50>;
		qcom,lut-row-legend = <10000 9800 9600 9400 9200 9000>,
			<8800 8600 8400 8200 8000 7800>,
			<7600 7400 7200 7000 6800 6600>,
			<6400 6200 6000 5800 5600 5400>,
			<5200 5000 4800 4600 4400 4200>,
			<4000 3800 3600 3400 3200 3000>,
			<2800 2600 2400 2200 2000 1800>,
			<1600 1400 1200 1000 900 800>,
			<700 600 500 400 300 200>,
			<100 0>;
		qcom,lut-data = <6481 5761 5338 5129 5080 5073>,
			<6482 5765 5338 5126 5080 5072>,
			<6479 5767 5337 5124 5079 5072>,
			<6473 5768 5335 5122 5079 5072>,
			<6464 5768 5333 5122 5080 5073>,
			<6455 5767 5330 5121 5080 5073>,
			<6443 5763 5326 5122 5081 5073>,
			<6429 5756 5322 5123 5082 5074>,
			<6412 5748 5321 5124 5083 5075>,
			<6391 5739 5321 5126 5084 5076>,
			<6380 5734 5321 5128 5086 5077>,
			<6386 5754 5325 5131 5088 5078>,
			<6399 5787 5332 5134 5090 5080>,
			<6384 5787 5338 5138 5093 5082>,
			<6259 5747 5343 5144 5096 5084>,
			<6163 5706 5346 5150 5100 5087>,
			<6162 5682 5343 5155 5104 5090>,
			<6163 5662 5337 5159 5108 5093>,
			<6163 5648 5328 5166 5114 5098>,
			<6160 5637 5309 5175 5123 5106>,
			<6155 5628 5290 5179 5128 5111>,
			<6137 5619 5274 5160 5117 5103>,
			<6110 5612 5260 5132 5098 5089>,
			<6104 5602 5254 5120 5087 5080>,
			<6121 5588 5251 5112 5079 5072>,
			<6144 5580 5249 5110 5076 5069>,
			<6166 5587 5250 5111 5076 5069>,
			<6189 5603 5252 5113 5077 5070>,
			<6213 5623 5253 5115 5079 5071>,
			<6239 5648 5252 5118 5082 5073>,
			<6266 5676 5251 5120 5086 5076>,
			<6294 5704 5255 5124 5091 5080>,
			<6322 5734 5263 5127 5095 5085>,
			<6352 5766 5273 5129 5096 5088>,
			<6383 5801 5286 5131 5097 5089>,
			<6416 5839 5301 5132 5097 5090>,
			<6450 5879 5316 5132 5091 5084>,
			<6485 5922 5333 5131 5083 5075>,
			<6520 5970 5350 5131 5083 5074>,
			<6554 6023 5368 5131 5086 5078>,
			<6588 6081 5387 5131 5089 5083>,
			<6626 6146 5410 5137 5092 5087>,
			<6667 6220 5437 5141 5093 5089>,
			<6721 6303 5471 5141 5086 5078>,
			<6793 6404 5516 5144 5085 5075>,
			<6843 6457 5530 5148 5094 5088>,
			<6861 6507 5561 5158 5107 5103>,
			<6932 6586 5605 5172 5123 5118>,
			<7020 6672 5665 5189 5135 5130>,
			<7113 6759 5725 5201 5134 5122>,
			<7224 6833 5763 5181 5107 5095>,
			<7392 6922 5833 5186 5105 5094>,
			<7675 7075 5986 5211 5114 5102>,
			<8666 7320 6203 5256 5141 5126>,
			<8666 7320 6203 5256 5141 5126>,
			<8666 7320 6203 5256 5141 5126>;
	};

};
